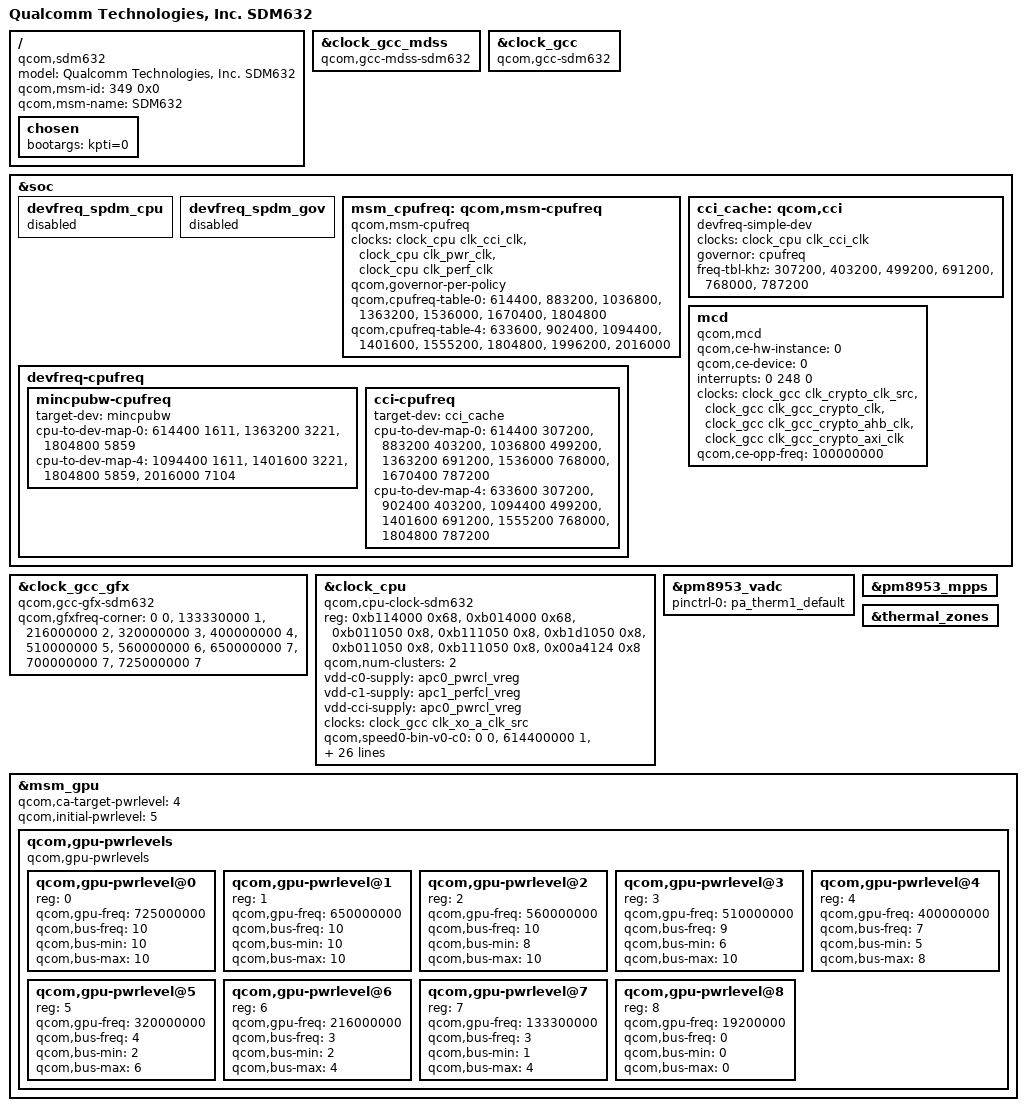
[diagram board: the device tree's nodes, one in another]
/*
 * Copyright (c) 2018, The Linux Foundation. All rights reserved.
 *
 * This program is free software; you can redistribute it and/or modify
 * it under the terms of the GNU General Public License version 2 and
 * only version 2 as published by the Free Software Foundation.
 *
 * This program is distributed in the hope that it will be useful,
 * but WITHOUT ANY WARRANTY; without even the implied warranty of
 * MERCHANTABILITY or FITNESS FOR A PARTICULAR PURPOSE.  See the
 * GNU General Public License for more details.
 */

#include "msm8953.dtsi"
#include "sdm632-cpu.dtsi"
#include "sdm632-regulator.dtsi"

/ {
	model = "Qualcomm Technologies, Inc. SDM632";
	compatible = "qcom,sdm632";
	qcom,msm-id = <349 0x0>;
	qcom,msm-name = "SDM632";

	chosen {
		bootargs = "kpti=0";
	};
};

&clock_gcc_mdss {
	compatible = "qcom,gcc-mdss-sdm632";
};

&clock_gcc {
	compatible = "qcom,gcc-sdm632";
};

&soc {
	devfreq_spdm_cpu {
		status = "disabled";
	};

	devfreq_spdm_gov {
		status = "disabled";
	};
};

&clock_gcc_gfx {
	compatible = "qcom,gcc-gfx-sdm632";
	qcom,gfxfreq-corner =
		 <         0   0 >,
		 < 133330000   1 >,  /* Min SVS   */
		 < 216000000   2 >,  /* Low SVS   */
		 < 320000000   3 >,  /* SVS       */
		 < 400000000   4 >,  /* SVS Plus  */
		 < 510000000   5 >,  /* NOM       */
		 < 560000000   6 >,  /* Nom Plus  */
		 < 650000000   7 >,  /* Turbo     */
		 < 700000000   7 >,  /* Turbo     */
		 < 725000000   7 >;  /* Turbo     */
};

&clock_cpu {
	/delete-property/ vdd-cl-supply;
	compatible = "qcom,cpu-clock-sdm632";
	reg =   <0xb114000  0x68>,
		<0xb014000  0x68>,
		<0xb011050  0x8>,
		<0xb111050  0x8>,
		<0xb1d1050  0x8>,
		<0xb011050  0x8>,
		<0xb111050  0x8>,
		<0x00a4124  0x8>;
	reg-names = "rcgwr-c0-base", "rcgwr-c1-base",
		    "apcs-c1-rcg-base", "apcs-c0-rcg-base",
		    "apcs-cci-rcg-base", "c1-mux",
		    "c0-mux", "efuse";
	qcom,num-clusters = <2>;
	vdd-c0-supply = <&apc0_pwrcl_vreg>;
	vdd-c1-supply = <&apc1_perfcl_vreg>;
	vdd-cci-supply = <&apc0_pwrcl_vreg>;
	clocks = <&clock_gcc clk_xo_a_clk_src>;
	clock-names = "xo_a";
	qcom,speed0-bin-v0-c0 =
		<          0 0>,
		<   614400000 1>,
		<   883200000 2>,
		<  1036800000 3>,
		<  1363200000 4>,
		<  1536000000 5>,
		<  1670400000 6>,
		<  1804800000 7>;
	qcom,speed0-bin-v0-c1 =
		<          0 0>,
		<   633600000 1>,
		<   902400000 2>,
		<  1094400000 3>,
		<  1401600000 4>,
		<  1555200000 5>,
		<  1804800000 6>;
	qcom,speed0-bin-v0-cci =
		<          0 0>,
		<  307200000 1>,
		<  403200000 2>,
		<  499200000 3>,
		<  691200000 4>,
		<  768000000 5>,
		<  787200000 6>;

	qcom,speed6-bin-v0-c0 =
		<          0 0>,
		<   614400000 1>,
		<   883200000 2>,
		<  1036800000 3>,
		<  1363200000 4>,
		<  1536000000 5>,
		<  1670400000 6>,
		<  1804800000 7>;
	qcom,speed6-bin-v0-c1 =
		<          0 0>,
		<   633600000 1>,
		<   902400000 2>,
		<  1094400000 3>,
		<  1401600000 4>,
		<  1555200000 5>,
		<  1804800000 6>;
	qcom,speed6-bin-v0-cci =
		<          0 0>,
		<  307200000 1>,
		<  403200000 2>,
		<  499200000 3>,
		<  691200000 4>,
		<  768000000 5>,
		<  787200000 6>;

	qcom,speed2-bin-v0-c0 =
		<          0 0>,
		<   614400000 1>,
		<   883200000 2>,
		<  1036800000 3>,
		<  1363200000 4>,
		<  1536000000 5>,
		<  1670400000 6>,
		<  1804800000 7>;
	qcom,speed2-bin-v0-c1 =
		<          0 0>,
		<   633600000 1>,
		<   902400000 2>,
		<  1094400000 3>,
		<  1401600000 4>,
		<  1555200000 5>,
		<  1804800000 6>,
		<  2016000000 7>;
	qcom,speed2-bin-v0-cci =
		<          0 0>,
		<  307200000 1>,
		<  403200000 2>,
		<  499200000 3>,
		<  691200000 4>,
		<  768000000 5>,
		<  787200000 6>;

	#clock-cells = <1>;
};

&soc {
	/delete-node/ qcom,msm-cpufreq;
	msm_cpufreq: qcom,msm-cpufreq {
		compatible = "qcom,msm-cpufreq";
		clock-names =
			"l2_clk",
			"cpu0_clk",
			"cpu4_clk";
		clocks =
			<&clock_cpu clk_cci_clk >,
			<&clock_cpu clk_pwr_clk >,
			<&clock_cpu clk_perf_clk >;

		qcom,governor-per-policy;

		qcom,cpufreq-table-0 =
			<  614400 >,
			<  883200 >,
			< 1036800 >,
			< 1363200 >,
			< 1536000 >,
			< 1670400 >,
			< 1804800 >;

		qcom,cpufreq-table-4 =
			<  633600 >,
			<  902400 >,
			< 1094400 >,
			< 1401600 >,
			< 1555200 >,
			< 1804800 >,
			< 1996200 >,
			< 2016000 >;
	};

	cci_cache: qcom,cci {
		compatible = "devfreq-simple-dev";
		clock-names = "devfreq_clk";
		clocks = <&clock_cpu clk_cci_clk >;
		governor = "cpufreq";
		freq-tbl-khz =
			<  307200 >,
			<  403200 >,
			<  499200 >,
			<  691200 >,
			<  768000 >,
			<  787200 >;
	};

	/delete-node/ devfreq-cpufreq;
	devfreq-cpufreq {
		mincpubw-cpufreq {
			target-dev = <&mincpubw>;
			cpu-to-dev-map-0 =
				<  614400 1611>,
				< 1363200 3221>,
				< 1804800 5859>;
			cpu-to-dev-map-4 =
				< 1094400 1611>,
				< 1401600 3221>,
				< 1804800 5859>,
				< 2016000 7104>;
		};

		cci-cpufreq {
			target-dev = <&cci_cache>;
			cpu-to-dev-map-0 =
				<  614400 307200>,      /* SVS   */
				<  883200 403200>,
				< 1036800 499200>,
				< 1363200 691200>,      /* NOM   */
				< 1536000 768000>,      /* NOM+  */
				< 1670400 787200>;      /* TURBO */
			cpu-to-dev-map-4 =
				<  633600 307200>,      /* SVS   */
				<  902400 403200>,
				< 1094400 499200>,	/* SVS   */
				< 1401600 691200>,      /* NOM   */
				< 1555200 768000>,      /* NOM+  */
				< 1804800 787200>;      /* TURBO */
		};
	};

	mcd {
		compatible = "qcom,mcd";
		qcom,ce-hw-instance = <0>;
		qcom,ce-device = <0>;
		interrupts = <0 248 0>;
		interrupt-names = "mcd_irq";
		clocks = <&clock_gcc clk_crypto_clk_src>,
			<&clock_gcc clk_gcc_crypto_clk>,
			<&clock_gcc clk_gcc_crypto_ahb_clk>,
			<&clock_gcc clk_gcc_crypto_axi_clk>;
		clock-names = "core_clk_src", "core_clk",
				"iface_clk", "bus_clk";
		qcom,ce-opp-freq = <100000000>;
	};
};

&pm8953_vadc {
	pinctrl-0 = <&pa_therm1_default>;
	/delete-node/ chan@13;
};

&pm8953_mpps {
	/delete-node/ case_therm;
};

&thermal_zones {
	/delete-node/ case-therm-adc;
	/delete-node/ case-therm-step;
};

#include "sdm632-coresight.dtsi"

/* GPU Overrides*/
&msm_gpu {

	qcom,ca-target-pwrlevel = <4>;
	qcom,initial-pwrlevel = <5>;
	/delete-node/qcom,gpu-pwrlevels;

	/* Power levels */
	qcom,gpu-pwrlevels {
		#address-cells = <1>;
		#size-cells = <0>;

		compatible = "qcom,gpu-pwrlevels";
		/* TURBO LD0 */
		qcom,gpu-pwrlevel@0 {
			reg = <0>;
			qcom,gpu-freq = <725000000>;
			qcom,bus-freq = <10>;
			qcom,bus-min = <10>;
			qcom,bus-max = <10>;
		};

		/* TURBO */
		qcom,gpu-pwrlevel@1 {
			reg = <1>;
			qcom,gpu-freq = <650000000>;
			qcom,bus-freq = <10>;
			qcom,bus-min = <10>;
			qcom,bus-max = <10>;
		};

		/* NOM+ */
		qcom,gpu-pwrlevel@2 {
			reg = <2>;
			qcom,gpu-freq = <560000000>;
			qcom,bus-freq = <10>;
			qcom,bus-min = <8>;
			qcom,bus-max = <10>;
		};

		/* NOM */
		qcom,gpu-pwrlevel@3 {
			reg = <3>;
			qcom,gpu-freq = <510000000>;
			qcom,bus-freq = <9>;
			qcom,bus-min = <6>;
			qcom,bus-max = <10>;
		};

		/* SVS+ */
		qcom,gpu-pwrlevel@4 {
			reg = <4>;
			qcom,gpu-freq = <400000000>;
			qcom,bus-freq = <7>;
			qcom,bus-min = <5>;
			qcom,bus-max = <8>;
		};

		/* SVS */
		qcom,gpu-pwrlevel@5 {
			reg = <5>;
			qcom,gpu-freq = <320000000>;
			qcom,bus-freq = <4>;
			qcom,bus-min = <2>;
			qcom,bus-max = <6>;
		};

		/* Low SVS */
		qcom,gpu-pwrlevel@6 {
			reg = <6>;
			qcom,gpu-freq = <216000000>;
			qcom,bus-freq = <3>;
			qcom,bus-min = <2>;
			qcom,bus-max = <4>;
		};

		qcom,gpu-pwrlevel@7 {
			reg = <7>;
			qcom,gpu-freq = <133300000>;
			qcom,bus-freq = <3>;
			qcom,bus-min = <1>;
			qcom,bus-max = <4>;
		};
		/* XO */
		qcom,gpu-pwrlevel@8 {
			reg = <8>;
			qcom,gpu-freq = <19200000>;
			qcom,bus-freq = <0>;
			qcom,bus-min = <0>;
			qcom,bus-max = <0>;
		};
	};
};
